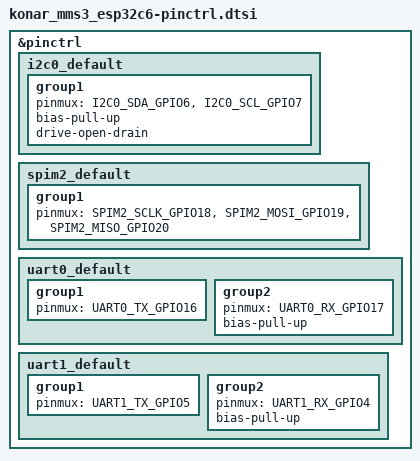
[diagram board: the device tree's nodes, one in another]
/*
 * Copyright (c) 2026 Your Name <your@email.com>
 *
 * SPDX-License-Identifier: Apache-2.0
 */

#include <zephyr/dt-bindings/pinctrl/esp32c6-pinctrl.h>

&pinctrl {
    i2c0_default: i2c0_default {
        group1 {
            pinmux = <I2C0_SDA_GPIO6>,
                     <I2C0_SCL_GPIO7>;
            bias-pull-up;
            drive-open-drain;
        };
    };
    spim2_default: spim2_default {
        group1 {
            pinmux = <SPIM2_SCLK_GPIO18>,
                     <SPIM2_MOSI_GPIO19>,
                     <SPIM2_MISO_GPIO20>;
        };
    };
    uart0_default: uart0_default {
        group1 {
            pinmux = <UART0_TX_GPIO16>;
        };
        group2 {
            pinmux = <UART0_RX_GPIO17>;
            bias-pull-up;
        };
    };
    uart1_default: uart1_default {
        group1 {
            pinmux = <UART1_TX_GPIO5>;
        };
        group2 {
            pinmux = <UART1_RX_GPIO4>;
            bias-pull-up;
        };
    };
};
